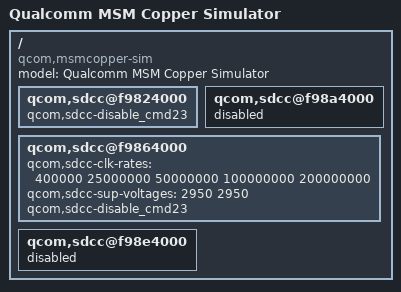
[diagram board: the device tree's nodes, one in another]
/* Copyright (c) 2012, Code Aurora Forum. All rights reserved.
 *
 * This program is free software; you can redistribute it and/or modify
 * it under the terms of the GNU General Public License version 2 and
 * only version 2 as published by the Free Software Foundation.
 *
 * This program is distributed in the hope that it will be useful,
 * but WITHOUT ANY WARRANTY; without even the implied warranty of
 * MERCHANTABILITY or FITNESS FOR A PARTICULAR PURPOSE.  See the
 * GNU General Public License for more details.
 */

/dts-v1/;

/include/ "msmcopper.dtsi"

/ {
	model = "Qualcomm MSM Copper Simulator";
	compatible = "qcom,msmcopper-sim", "qcom,msmcopper";

	qcom,sdcc@f9824000 {
		qcom,sdcc-disable_cmd23;
	};

	qcom,sdcc@f98a4000 {
		status = "disable";
	};

	qcom,sdcc@f9864000 {
		qcom,sdcc-clk-rates = <400000 25000000 50000000 100000000 200000000>;
		qcom,sdcc-sup-voltages = <2950 2950>;
		qcom,sdcc-disable_cmd23;
	};

	qcom,sdcc@f98e4000 {
		status = "disable";
	};
};
